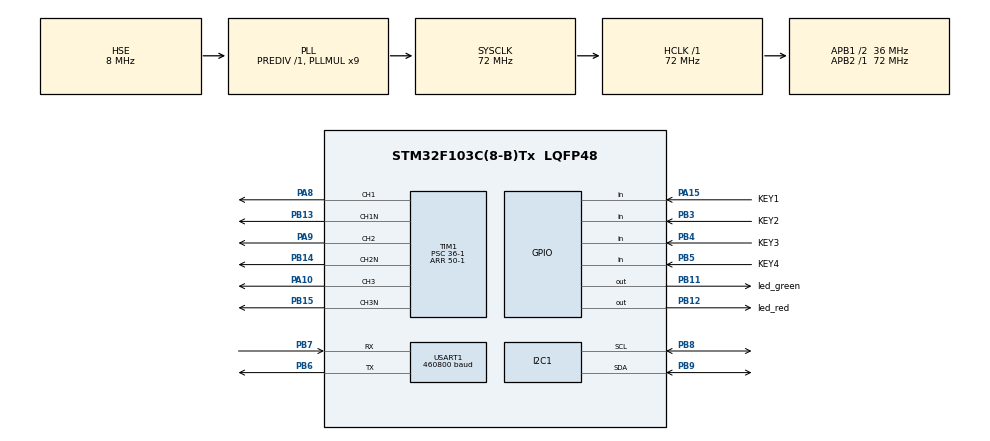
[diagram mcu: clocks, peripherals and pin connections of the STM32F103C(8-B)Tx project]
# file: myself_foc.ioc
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Dma.Request0=USART1_RX
Dma.Request1=USART1_TX
Dma.USART1_RX.0.Direction=DMA_PERIPH_TO_MEMORY
Dma.USART1_RX.0.Instance=DMA1_Channel5
Dma.USART1_RX.0.MemDataAlignment=DMA_MDATAALIGN_BYTE
Dma.USART1_RX.0.MemInc=DMA_MINC_ENABLE
Dma.USART1_RX.0.Mode=DMA_NORMAL
Dma.USART1_RX.0.PeriphDataAlignment=DMA_PDATAALIGN_BYTE
Dma.USART1_RX.0.PeriphInc=DMA_PINC_DISABLE
Dma.USART1_RX.0.Priority=DMA_PRIORITY_LOW
Dma.USART1_TX.1.Direction=DMA_MEMORY_TO_PERIPH
Dma.USART1_TX.1.Instance=DMA1_Channel4
Dma.USART1_TX.1.MemDataAlignment=DMA_MDATAALIGN_BYTE
Dma.USART1_TX.1.MemInc=DMA_MINC_ENABLE
Dma.USART1_TX.1.Mode=DMA_NORMAL
Dma.USART1_TX.1.PeriphDataAlignment=DMA_PDATAALIGN_BYTE
Dma.USART1_TX.1.PeriphInc=DMA_PINC_DISABLE
Dma.USART1_TX.1.Priority=DMA_PRIORITY_LOW
I2C1.I2C_Mode=I2C_Fast
Mcu.Family=STM32F1
Mcu.Name=STM32F103C(8-B)Tx
Mcu.Package=LQFP48
NVIC.DMA1_Channel4_IRQn=true\:0\:0\:false\:false\:true\:false\:true\:true
NVIC.DMA1_Channel5_IRQn=true\:0\:0\:false\:false\:true\:false\:true\:true
NVIC.PriorityGroup=NVIC_PRIORITYGROUP_4
NVIC.TIM1_CC_IRQn=true\:0\:0\:false\:false\:true\:true\:true\:true
NVIC.USART1_IRQn=true\:0\:0\:false\:false\:true\:true\:true\:true
PA10.Signal=S_TIM1_CH3
PA13.Mode=Serial_Wire
PA13.Signal=SYS_JTMS-SWDIO
PA14.Mode=Serial_Wire
PA14.Signal=SYS_JTCK-SWCLK
PA15.GPIO_Label=KEY1
PA15.GPIO_PuPd=GPIO_PULLUP
PA15.Signal=GPIO_Input
PA8.Signal=S_TIM1_CH1
PA9.Signal=S_TIM1_CH2
PB11.GPIO_Label=led_green
PB11.GPIO_PuPd=GPIO_PULLUP
PB11.Signal=GPIO_Output
PB12.GPIO_Label=led_red
PB12.GPIO_PuPd=GPIO_PULLUP
PB12.Signal=GPIO_Output
PB13.Mode=PWM Generation1 CH1 CH1N
PB13.Signal=TIM1_CH1N
PB14.Mode=PWM Generation2 CH2 CH2N
PB14.Signal=TIM1_CH2N
PB15.Mode=PWM Generation3 CH3 CH3N
PB15.Signal=TIM1_CH3N
PB3.GPIO_Label=KEY2
PB3.GPIO_PuPd=GPIO_PULLUP
PB3.Signal=GPIO_Input
PB4.GPIO_Label=KEY3
PB4.GPIO_PuPd=GPIO_PULLUP
PB4.Signal=GPIO_Input
PB5.GPIO_Label=KEY4
PB5.GPIO_PuPd=GPIO_PULLUP
PB5.Signal=GPIO_Input
PB6.Mode=Asynchronous
PB6.Signal=USART1_TX
PB7.Mode=Asynchronous
PB7.Signal=USART1_RX
PB8.Mode=I2C
PB8.Signal=I2C1_SCL
PB9.Mode=I2C
PB9.Signal=I2C1_SDA
PD0-OSC_IN.Mode=HSE-External-Oscillator
PD0-OSC_IN.Signal=RCC_OSC_IN
PD1-OSC_OUT.Mode=HSE-External-Oscillator
PD1-OSC_OUT.Signal=RCC_OSC_OUT
ProjectManager.HeapSize=0x200
ProjectManager.StackSize=0x400
ProjectManager.TargetToolchain=MDK-ARM V5.32
RCC.AHBFreq_Value=72000000
RCC.APB1CLKDivider=RCC_HCLK_DIV2
RCC.APB1Freq_Value=36000000
RCC.APB1TimFreq_Value=72000000
RCC.APB2Freq_Value=72000000
RCC.APB2TimFreq_Value=72000000
RCC.HCLKFreq_Value=72000000
RCC.PLLMUL=RCC_PLL_MUL9
RCC.PLLSourceVirtual=RCC_PLLSOURCE_HSE
RCC.SYSCLKFreq_VALUE=72000000
RCC.SYSCLKSource=RCC_SYSCLKSOURCE_PLLCLK
RCC.USBFreq_Value=72000000
SH.S_TIM1_CH1.0=TIM1_CH1,PWM Generation1 CH1 CH1N
SH.S_TIM1_CH2.0=TIM1_CH2,PWM Generation2 CH2 CH2N
SH.S_TIM1_CH3.0=TIM1_CH3,PWM Generation3 CH3 CH3N
TIM1.Channel-PWM\ Generation1\ CH1\ CH1N=TIM_CHANNEL_1
TIM1.Channel-PWM\ Generation2\ CH2\ CH2N=TIM_CHANNEL_2
TIM1.Channel-PWM\ Generation3\ CH3\ CH3N=TIM_CHANNEL_3
TIM1.Channel-PWM\ Generation4\ No\ Output=TIM_CHANNEL_4
TIM1.CounterMode=TIM_COUNTERMODE_CENTERALIGNED1
TIM1.Period=50-1
TIM1.Prescaler=36-1
TIM1.Pulse-PWM\ Generation4\ No\ Output=48
USART1.BaudRate=460800
USART1.VirtualMode=VM_ASYNC
VP_TIM1_VS_no_output4.Mode=PWM Generation4 No Output
board=custom

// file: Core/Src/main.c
/* USER CODE BEGIN Header */
/**
  ******************************************************************************
  * @file           : main.c
  * @brief          : Main program body
  ******************************************************************************
  * @attention
  *
  * Copyright (c) 2026 STMicroelectronics.
  * All rights reserved.
  *
  * This software is licensed under terms that can be found in the LICENSE file
  * in the root directory of this software component.
  * If no LICENSE file comes with this software, it is provided AS-IS.
  *
  ******************************************************************************
  */
/* USER CODE END Header */
#include "main.h"
#include "dma.h"
#include "i2c.h"
#include "tim.h"
#include "usart.h"
#include "gpio.h"

/* USER CODE BEGIN Includes */
#include "bsp_system.h"
/* USER CODE END Includes */

void SystemClock_Config(void);

int main(void)
{

  /* MCU Configuration--------------------------------------------------------*/

  /* Reset of all peripherals, Initializes the Flash interface and the Systick. */
  HAL_Init();

  /* Configure the system clock */
  SystemClock_Config();

  /* Initialize all configured peripherals */
  MX_GPIO_Init();
  MX_DMA_Init();
  MX_USART1_UART_Init();
  MX_TIM1_Init();
  MX_I2C1_Init();
  /* USER CODE BEGIN 2 */
  CpuStat_Init();
  scheduler_init();
  Motor_StateMachine_Init(&MotorSystem);
  /* USER CODE END 2 */

  /* Infinite loop */
  /* USER CODE BEGIN WHILE */
  while (1)
  {
	/* 编码器限频到 1kHz。400kHz 下每次读约 0.12ms → 约 12% CPU
	 * 千万不要每圈都读：阻塞式读会把主循环的时间全吃掉 */
	static uint32_t enc_tick = 0;
	if((HAL_GetTick() - enc_tick) >= 1U)
	{
		enc_tick = HAL_GetTick();
		uint16_t data = AS5600_ReadData();
		if(data != 0xFFFF)                 /* 读失败就不更新角度 */
		{
			Encoder_UpData(&MotorSystem.Encoder,data);
			/* 打时间戳 + 解算实测转速 + 原子发布给中断（角度预测用）*/
			Encoder_Speed_Update(&MotorSystem.Encoder,DWT->CYCCNT);
		}
	}
	  scheduler_run();
	  Vofa_Send_Task();
    /* USER CODE END WHILE */

  }
}

void SystemClock_Config(void)
{
  RCC_OscInitTypeDef RCC_OscInitStruct = {0};
  RCC_ClkInitTypeDef RCC_ClkInitStruct = {0};

  /** Initializes the RCC Oscillators according to the specified parameters
  * in the RCC_OscInitTypeDef structure.
  */
  RCC_OscInitStruct.OscillatorType = RCC_OSCILLATORTYPE_HSE;
  RCC_OscInitStruct.HSEState = RCC_HSE_ON;
  RCC_OscInitStruct.HSEPredivValue = RCC_HSE_PREDIV_DIV1;
  RCC_OscInitStruct.HSIState = RCC_HSI_ON;
  RCC_OscInitStruct.PLL.PLLState = RCC_PLL_ON;
  RCC_OscInitStruct.PLL.PLLSource = RCC_PLLSOURCE_HSE;
  RCC_OscInitStruct.PLL.PLLMUL = RCC_PLL_MUL9;
  if (HAL_RCC_OscConfig(&RCC_OscInitStruct) != HAL_OK)
  {
    Error_Handler();
  }

  /** Initializes the CPU, AHB and APB buses clocks
  */
  RCC_ClkInitStruct.ClockType = RCC_CLOCKTYPE_HCLK|RCC_CLOCKTYPE_SYSCLK
                              |RCC_CLOCKTYPE_PCLK1|RCC_CLOCKTYPE_PCLK2;
  RCC_ClkInitStruct.SYSCLKSource = RCC_SYSCLKSOURCE_PLLCLK;
  RCC_ClkInitStruct.AHBCLKDivider = RCC_SYSCLK_DIV1;
  RCC_ClkInitStruct.APB1CLKDivider = RCC_HCLK_DIV2;
  RCC_ClkInitStruct.APB2CLKDivider = RCC_HCLK_DIV1;

  if (HAL_RCC_ClockConfig(&RCC_ClkInitStruct, FLASH_LATENCY_2) != HAL_OK)
  {
    Error_Handler();
  }
}

void Error_Handler(void)
{
  __disable_irq();
  while (1)
  {
  }
}
